# STM32F46_79x register map
File version: 1.0
Registers are 32-bit, read-write, reset 0x0 unless marked. A register's access mark holds for its fields unless they carry their own. Offsets are from the block's base; [hi:lo] are bit positions; {n}, {i} and the like mark numbered series.

## SDIO — Secure digital input/output interface
Base 0x40012C00
0x00 POWER — power control register
  [1:0] PWRCTRL
    0=Power_OFF (The clock to card is stopped.); 3=Power_ON (The card is clocked.)
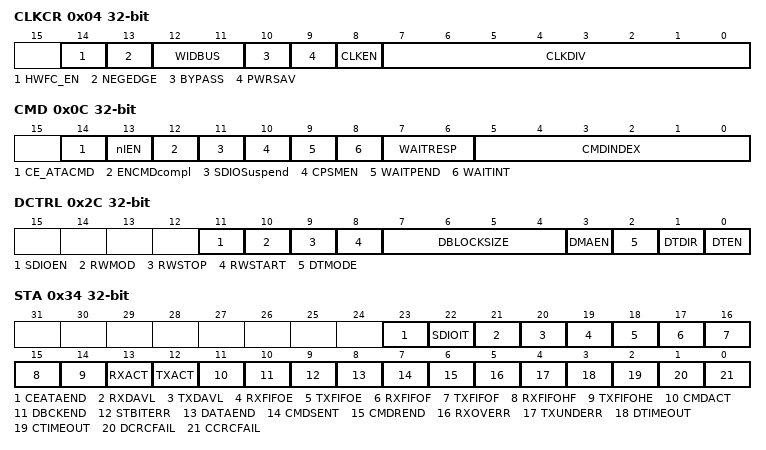
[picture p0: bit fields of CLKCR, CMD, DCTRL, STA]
0x04 CLKCR — SDI clock control register
  [14] HWFC_EN — HW Flow Control enable
  [13] NEGEDGE — SDIO_CK dephasing selection bit
    0=Edge_Rising (Cmd and Data changed on the SDMMCCLK falling edge succeeding the rising edge of SDMMC_CK.); 1=Edge_Falling (Cmd and Data changed on the SDMMC_CK falling edge.)
  [12:11] WIDBUS — Wide bus mode enable bit
    0=Bus_Wide_1b (Default bus mode: SDMMC_D0 is used.); 1=Bus_Wide_4b (4-wide bus mode: SDMMC_D[3:0] used.); 2=Bus_Wide_8b (8-wide bus mode: SDMMC_D[7:0] used.)
  [10] BYPASS — Clock divider bypass enable bit
  [9] PWRSAV — Power saving configuration bit
  [8] CLKEN — Clock enable bit
  [7:0] CLKDIV — Clock divide factor
0x08 ARG — argument register
  [31:0] CMDARG — Command argument
0x0C CMD — command register
  [14] CE_ATACMD — CE-ATA command
  [13] nIEN — not Interrupt Enable
  [12] ENCMDcompl — Enable CMD completion
  [11] SDIOSuspend — SD I/O suspend command
  [10] CPSMEN — Command path state machine (CPSM) Enable bit
  [9] WAITPEND — CPSM Waits for ends of data transfer (CmdPend internal signal).
  [8] WAITINT — CPSM waits for interrupt request
  [7:6] WAITRESP — Wait for response bits
    0=No response, expect CMDSENT flag; 1=Short response, expect CMDREND or CCRCFAIL flag; 3=Long response, expect CMDREND or CCRCFAIL flag
  [5:0] CMDINDEX — Command index
0x10 RESPCMD ro — command response register
  [5:0] RESPCMD — Response command index
{0x10+4i} RESP{i} ro (i=1..4) — response 1..4 register
  [31:0] CARDSTATUS{i} — see Table 132.
0x24 DTIMER — data timer register
  [31:0] DATATIME — Data timeout period
0x28 DLEN — data length register
  [24:0] DATALENGTH — Data length value
0x2C DCTRL — data control register
  [11] SDIOEN — SD I/O enable functions
  [10] RWMOD — Read wait mode
  [9] RWSTOP — Read wait stop
  [8] RWSTART — Read wait start
  [7:4] DBLOCKSIZE — Data block size
    0=Block_1b (Block length = 2**0 = 1 byte); 1=Block_2b (Block length = 2**1 = 2 byte); 2=Block_4b (Block length = 2**2 = 4 byte); 3=Block_8b (Block length = 2**3 = 8 byte); 4=Block_16b (Block length = 2**4 = 16 byte); 5=Block_32b (Block length = 2**5 = 32 byte); 6=Block_64b (Block length = 2**6 = 64 byte); 7=Block_128b (Block length = 2**7 = 128 byte); 8=Block_256b (Block length = 2**8 = 256 byte); 9=Block_512b (Block length = 2**9 = 512 byte); 10=Block_1024b (Block length = 2**10 = 1024 byte); 11=Block_2048b (Block length = 2**11 = 2048 byte); 12=Block_4096b (Block length = 2**12 = 4096 byte); 13=Block_8192b (Block length = 2**13 = 8192 byte); 14=Block_16384b (Block length = 2**14 = 16384 byte)
  [3] DMAEN — DMA enable bit
  [2] DTMODE — Data transfer mode selection 1: Stream or SDIO multibyte data transfer.
    0=Block data transfer; 1=Stream or SDIO multibyte data transfer
  [1] DTDIR — Data transfer direction selection
    0=Controller_To_Card (Data is sent to the card); 1=Card_To_Controller (Data is read from the card)
  [0] DTEN
0x30 DCOUNT ro — data counter register
  [24:0] DATACOUNT — Data count value
0x34 STA ro — status register
  [23] CEATAEND — CE-ATA command completion signal received for CMD61
  [22] SDIOIT — SDIO interrupt received
  [21] RXDAVL — Data available in receive FIFO
  [20] TXDAVL — Data available in transmit FIFO
  [19] RXFIFOE — Receive FIFO empty
  [18] TXFIFOE — Transmit FIFO empty
  [17] RXFIFOF — Receive FIFO full
  [16] TXFIFOF — Transmit FIFO full
  [15] RXFIFOHF — Receive FIFO half full: there are at least 8 words in the FIFO
  [14] TXFIFOHE — Transmit FIFO half empty: at least 8 words can be written into the FIFO
  [13] RXACT — Data receive in progress
  [12] TXACT — Data transmit in progress
  [11] CMDACT — Command transfer in progress
  [10] DBCKEND — Data block sent/received (CRC check passed)
  [9] STBITERR — Start bit not detected on all data signals in wide bus mode
  [8] DATAEND — Data end (data counter, SDIDCOUNT, is zero)
  [7] CMDSENT — Command sent (no response required)
  [6] CMDREND — Command response received (CRC check passed)
  [5] RXOVERR — Received FIFO overrun error
  [4] TXUNDERR — Transmit FIFO underrun error
  [3] DTIMEOUT — Data timeout
  [2] CTIMEOUT — Command response timeout
  [1] DCRCFAIL — Data block sent/received (CRC check failed)
  [0] CCRCFAIL — Command response received (CRC check failed)
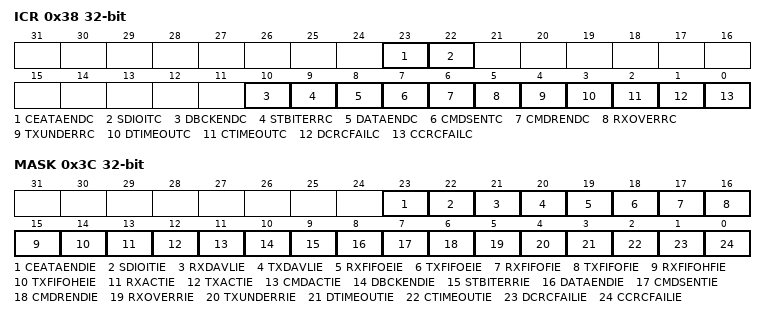
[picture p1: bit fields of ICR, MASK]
0x38 ICR — interrupt clear register
  [23] CEATAENDC — CEATAEND flag clear bit
  [22] SDIOITC — SDIOIT flag clear bit
  [10] DBCKENDC — DBCKEND flag clear bit
  [9] STBITERRC — STBITERR flag clear bit
  [8] DATAENDC — DATAEND flag clear bit
  [7] CMDSENTC — CMDSENT flag clear bit
  [6] CMDRENDC — CMDREND flag clear bit
  [5] RXOVERRC — RXOVERR flag clear bit
  [4] TXUNDERRC — TXUNDERR flag clear bit
  [3] DTIMEOUTC — DTIMEOUT flag clear bit
  [2] CTIMEOUTC — CTIMEOUT flag clear bit
  [1] DCRCFAILC — DCRCFAIL flag clear bit
  [0] CCRCFAILC — CCRCFAIL flag clear bit
0x3C MASK
  [23] CEATAENDIE — CE-ATA command completion signal received interrupt enable
  [22] SDIOITIE — SDIO mode interrupt received interrupt enable
  [21] RXDAVLIE — Data available in Rx FIFO interrupt enable
  [20] TXDAVLIE — Data available in Tx FIFO interrupt enable
  [19] RXFIFOEIE — Rx FIFO empty interrupt enable
  [18] TXFIFOEIE — Tx FIFO empty interrupt enable
  [17] RXFIFOFIE — Rx FIFO full interrupt enable
  [16] TXFIFOFIE — Tx FIFO full interrupt enable
  [15] RXFIFOHFIE — Rx FIFO half full interrupt enable
  [14] TXFIFOHEIE — Tx FIFO half empty interrupt enable
  [13] RXACTIE — Data receive acting interrupt enable
  [12] TXACTIE — Data transmit acting interrupt enable
  [11] CMDACTIE — Command acting interrupt enable
  [10] DBCKENDIE — Data block end interrupt enable
  [9] STBITERRIE — Start bit error interrupt enable
  [8] DATAENDIE — Data end interrupt enable
  [7] CMDSENTIE — Command sent interrupt enable
  [6] CMDRENDIE — Command response received interrupt enable
  [5] RXOVERRIE — Rx FIFO overrun error interrupt enable
  [4] TXUNDERRIE — Tx FIFO underrun error interrupt enable
  [3] DTIMEOUTIE — Data timeout interrupt enable
  [2] CTIMEOUTIE — Command timeout interrupt enable
  [1] DCRCFAILIE — Data CRC fail interrupt enable
  [0] CCRCFAILIE — Command CRC fail interrupt enable
0x48 FIFOCNT ro — FIFO counter register
  [23:0] FIFOCOUNT — Remaining number of words to be written to or read from the FIFO.
0x80 FIFO — data FIFO register
  [31:0] FIFOData — Receive and transmit FIFO data
